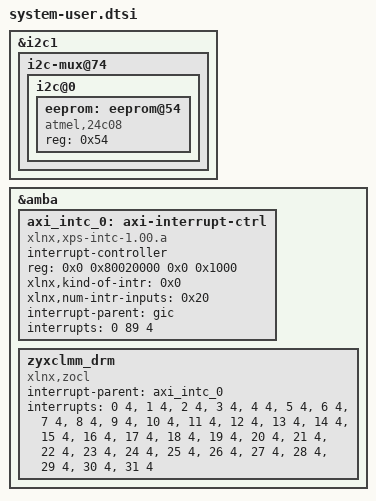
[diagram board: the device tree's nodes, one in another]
/include/ "system-conf.dtsi"
/{
};

&i2c1 {

	/* FIXME PL i2c via PCA9306 - u45 */
	/* FIXME MSP430 - u41 - not detected */
	i2c-mux@74 { /* u34 */
		i2c@0 { /* i2c mw 74 0 1 */
			/*
			 * IIC_EEPROM 1kB memory which uses 256B blocks
			 * where every block has different address.
			 *    0 - 256B address 0x54
			 * 256B - 512B address 0x55
			 * 512B - 768B address 0x56
			 * 768B - 1024B address 0x57
			 */
			eeprom: eeprom@54 { /* u23 */
				compatible = "atmel,24c08";
				reg = <0x54>;
			};
		};
	};
};

&amba {
	axi_intc_0: axi-interrupt-ctrl {
		#interrupt-cells = <2>;
		compatible = "xlnx,xps-intc-1.00.a";
		interrupt-controller;
		reg = <0x0 0x80020000 0x0 0x1000>;
		xlnx,kind-of-intr = <0x0>;
		xlnx,num-intr-inputs = <0x20>;
		interrupt-parent = <&gic>;
		interrupts = <0 89 4>;
	};

	zyxclmm_drm {
		compatible = "xlnx,zocl";
		status = "okay";
		interrupt-parent = <&axi_intc_0>;
		interrupts = <0  4>, <1  4>, <2  4>, <3  4>,
			     <4  4>, <5  4>, <6  4>, <7  4>,
			     <8  4>, <9  4>, <10 4>, <11 4>,
			     <12 4>, <13 4>, <14 4>, <15 4>,
			     <16 4>, <17 4>, <18 4>, <19 4>,
			     <20 4>, <21 4>, <22 4>, <23 4>,
			     <24 4>, <25 4>, <26 4>, <27 4>,
			     <28 4>, <29 4>, <30 4>, <31 4>;
	};
};

